# PCIE_CAP_REGS register map
Vendor: Texas Instruments
Peripheral module from a debugger description file (folder 66AK2G0x_66AK2G1x).
Registers are 32-bit, read-only, reset 0x0 unless marked. A register's access mark holds for its fields unless they carry their own. Offsets are as the file gives them; lines under a group give offsets from that group; [hi:lo] are bit positions; {n}, {i} and the like mark numbered series; 'fields as' and 'values as' point back to an identical list; <NAME> marks a mode.

## PCIE_CAP_REGS
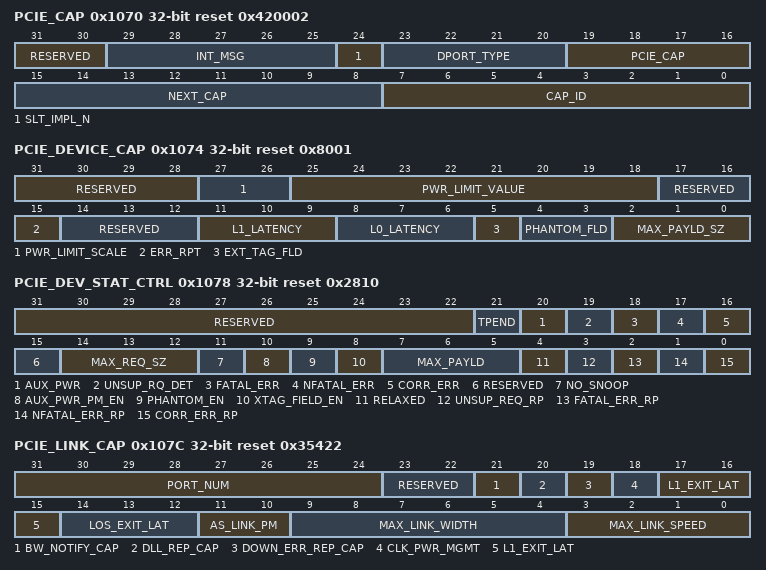
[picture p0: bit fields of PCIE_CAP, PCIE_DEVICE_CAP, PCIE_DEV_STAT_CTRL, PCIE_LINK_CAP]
0x1070 PCIE_CAP reset 0x420002
  [31:30] RESERVED — Reads return 0 and writes have no effect.
  [29:25] INT_MSG — Interrupt Message Number. Updated by hardware and writable through internal bus Interface.
  [24] SLT_IMPL_N — Slot Implemented. Writable from internal bus interface.
  [23:20] DPORT_TYPE — Device Port Type.
  [19:16] PCIE_CAP — PCI Express Capability Version
  [15:8] NEXT_CAP — Next capability pointer. Writable from internal bus interface.
  [7:0] CAP_ID — PCIe Capability ID.
0x1074 PCIE_DEVICE_CAP reset 0x8001
  [31:28] RESERVED — Reads return 0 and writes have no effect.
  [27:26] PWR_LIMIT_SCALE — Captured Slot Power Limit Scale. For upstream ports (EP ports) only.
  [25:18] PWR_LIMIT_VALUE — Captured Slot Power Limit Value. For upstream ports (EP ports) only.
  [17:16] RESERVED — Reads return 0 and writes have no effect.
  [15] ERR_RPT — Role-based Error Reporting. Writable from internal bus interface.
  [14:12] RESERVED — Reads return 0 and writes have no effect.
  [11:9] L1_LATENCY — Endpoint L1 Acceptable Latency. Must be
  [8:6] L0_LATENCY — Endpoint L0s Acceptable Latency. Must be
  [5] EXT_TAG_FLD — Extended Tag Field Supported. Writable from internal interface but should not be as the hardware is not capable.
  [4:3] PHANTOM_FLD — Phantom Field Supported. Writable from internal bus interface.
  [2:0] MAX_PAYLD_SZ — Maximum Payload size supported. Writable from internal bus interface.
0x1078 PCIE_DEV_STAT_CTRL access not given reset 0x2810
  [31:22] RESERVED ro — Reads return 0 and writes have no effect.
  [21] TPEND ro — Transaction Pending
  [20] AUX_PWR ro — Auxiliary Power Detected
  [19] UNSUP_RQ_DET — Unsupported Request Detected (access RW1C)
  [18] FATAL_ERR — Fatal Error Detected (access RW1C)
  [17] NFATAL_ERR — Non-fatal Error Detected (access RW1C)
  [16] CORR_ERR — Correctable Error Detected (access RW1C)
  [15] RESERVED ro — Reads return 0 and writes have no effect.
  [14:12] MAX_REQ_SZ rw — Maximum Read Request Size
  [11] NO_SNOOP rw — Enable no snoop
  [10] AUX_PWR_PM_EN rw — AUX Power PM Enable
  [9] PHANTOM_EN rw — Phantom Function Enable
  [8] XTAG_FIELD_EN rw — Extended Tag Field Enable
  [7:5] MAX_PAYLD rw — Maximum Payload Size
  [4] RELAXED rw — Enable Relaxed Ordering
  [3] UNSUP_REQ_RP rw — Enable Unsupported Request Reporting
  [2] FATAL_ERR_RP rw — Fatal Error Reporting Enable
  [1] NFATAL_ERR_RP rw — Non-fatal Error Reporting Enable
  [0] CORR_ERR_RP rw — Correctable Error Reporting Enable
0x107C PCIE_LINK_CAP reset 0x35422
  [31:24] PORT_NUM — Port Number. Writable from internal bus interface.
  [23:22] RESERVED — Reads return 0 and writes have no effect.
  [21] BW_NOTIFY_CAP — Link Bandwidth Notification Capable.
  [20] DLL_REP_CAP — Data Link Layer Active Reporting Capable.
  [19] DOWN_ERR_REP_CAP — Surprise Down Error Reporting Capable. Not supported. Always zero.
  [18] CLK_PWR_MGMT — Clock Power Management. Writable from internal bus interface.For upstream ports (EP Ports), a value of 1h in this bit indicates that the component tolerates the removal of any reference clock(s) in the L1 and L2/L3 Ready Link states. A value of 0 indicates the reference clock(s) must not be removed in these Link states. For downstream ports (RC Ports), this bit is always 0.
  [17:15] L1_EXIT_LAT — L1 Exit Latency when common clock is used. Writable from internal bus interface.
  [14:12] LOS_EXIT_LAT — L0s Exit Latency. Writable from internal bus interface.
  [11:10] AS_LINK_PM — Active State Link Power Management Support. Writable from internal bus interface.
  [9:4] MAX_LINK_WIDTH — Maximum Link Width (×N – corresponding to N Lanes). Writable from internal bus interface.
  [3:0] MAX_LINK_SPEED — Maximum Link Speed. Writable from internal bus interface.
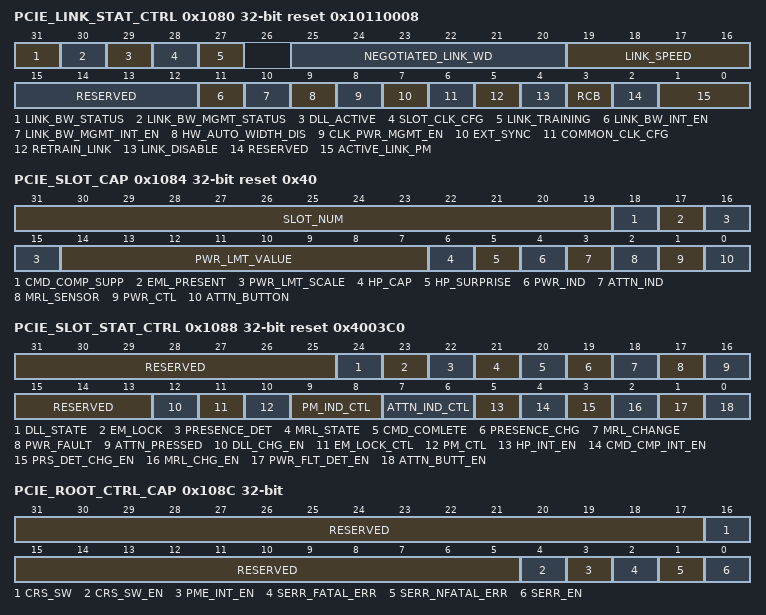
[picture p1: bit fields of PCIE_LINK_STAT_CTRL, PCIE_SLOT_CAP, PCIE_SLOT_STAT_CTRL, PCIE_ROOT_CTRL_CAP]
0x1080 PCIE_LINK_STAT_CTRL access not given reset 0x10110008
  [31] LINK_BW_STATUS — Link Autonomous Bandwidth Status.This bit is Set by hardware to indicate that hardware has autonomously changed Link speed or width, without the Port transitioning through DL_Down status, for reasons other than to attempt to correct unreliable Link operation. This bit must be set if the Physical Layer reports a speed or width change was initiated by the downstream component that was indicated as an autonomous change. Not applicable and reserved for EP. (access RW1C)
  [30] LINK_BW_MGMT_STATUS — Link Bandwidth Management Status.This bit is Set by hardware to indicate that either of the following has occurred without the Port transitioning through DL_Down status: • A Link retraining has completed following a write of 1b to the Retrain Link bit • Hardware has changed Link speed or width to attempt to correct unreliable Link operation, either through an LTSSM timeout or a higher level process. This bit must be set if the Physical Layer reports a speed or width change was initiated by the downstream component that was not indicated as an autonomous change. Not applicable and reserved for EP. (access RW1C)
  [29] DLL_ACTIVE ro — Data Link Layer ActiveThis bit indicates the status of the Data Link Control and Management State Machine. It returns a 1 to indicate the DL_Active state, 0 otherwise. Not applicable and reserved for EP.
  [28] SLOT_CLK_CFG ro — Slot Clock Configuration. Writable from internal bus interface.This bit indicates that the component uses the same physical reference clock that the platform provides on the connector.
  [27] LINK_TRAINING ro — Link Training. Not applicable to EP.
  [25:20] NEGOTIATED_LINK_WD ro — Negotiated Link Width. Set automatically by hardware after link initialization.
  [19:16] LINK_SPEED ro — Link Speed. Set automatically by hardware after link initialization.
  [15:12] RESERVED ro — Reads return 0 and writes have no effect.
  [11] LINK_BW_INT_EN ro — Link Autonomous Bandwidth Interrupt Enable. Not applicable and is reserved for EP.
  [10] LINK_BW_MGMT_INT_EN ro — Link Bandwidth Management Interrupt Enable. Not applicable and is reserved for EP.
  [9] HW_AUTO_WIDTH_DIS ro — Hardware Autonomous Width Disable. Not supported and hardwired to zero.
  [8] CLK_PWR_MGMT_EN rw — Enable Clock Power Management.
  [7] EXT_SYNC rw — Extended Synchronization.
  [6] COMMON_CLK_CFG rw — Common Clock Configuration.
  [5] RETRAIN_LINK rw — Retrain Link. Not applicable and reserved for EP.
  [4] LINK_DISABLE rw — This bit disables the link by directing the LTSSM to the Disabled state when set. Not applicable and is reserved for EP.
  [3] RCB ro — Read Completion Boundary. Writable via internal bus interface for RC.
  [2] RESERVED ro — Reads return 0 and writes have no effect.
  [1:0] ACTIVE_LINK_PM rw — Active State Link Power Management Control
0x1084 PCIE_SLOT_CAP reset 0x40
  [31:19] SLOT_NUM — Physical Slot Number. Writable from internal bus interface.
  [18] CMD_COMP_SUPP — No Command Complete Support. Writable from internal bus interface.When Set, this bit indicates that this slot does not generate software notification when an issued command is completed by the Hot-Plug Controller.
  [17] EML_PRESENT — Electromechanical Interlock Present. Writable from internal bus interface.When Set, this bit indicates that an Electromechanical Interlock is implemented on the chassis for this slot.
  [16:15] PWR_LMT_SCALE — Slot Power Limit Scale. Writable from internal bus interface.
  [14:7] PWR_LMT_VALUE — Slow Power Limit Value. Writable from internal bus interface.
  [6] HP_CAP — Hot Plug Capable. Writable from internal bus interface.
  [5] HP_SURPRISE — Hot Plug Surprise. Writable from internal bus interface.
  [4] PWR_IND — Power Indicator Present. Writable from internal bus interface.
  [3] ATTN_IND — Attention Indicator Present. Writable from internal bus interface.
  [2] MRL_SENSOR — MRL Sensor Present. Writable from internal bus interface.
  [1] PWR_CTL — Power Controller Present. Writable from internal bus interface. If there is no power controller, software must ensure that system power is up before reading Presence Detect state.
  [0] ATTN_BUTTON — Attention Indicator Present. Writable from internal bus interface.
0x1088 PCIE_SLOT_STAT_CTRL access not given reset 0x4003C0
  [31:25] RESERVED ro — Reads return 0 and writes have no effect.
  [24] DLL_STATE — Data Link Layer State Changed (access RW1C)
  [23] EM_LOCK ro — Electromechanical Lock Status
  [22] PRESENCE_DET ro — Presence Detect State
  [21] MRL_STATE ro — MRL Sensor State
  [20] CMD_COMLETE — Command Completed (access RW1C)
  [19] PRESENCE_CHG — Presence Detect Changed (access RW1C)
  [18] MRL_CHANGE — MRL Sensor Changed (access RW1C)
  [17] PWR_FAULT — Power Fault Detected (access RW1C)
  [16] ATTN_PRESSED — Attention Button Pressed. (access RW1C)
  [15:13] RESERVED ro — Reads return 0 and writes have no effect.
  [12] DLL_CHG_EN rw — Data Link Layer State Changed Enable.
  [11] EM_LOCK_CTL rw — Electromechanical Interlock Control.
  [10] PM_CTL rw — Power Controller Control
  [9:8] PM_IND_CTL rw — Power Indicator Control
  [7:6] ATTN_IND_CTL rw — Attention Indicator Control.
  [5] HP_INT_EN rw — Hot Plug Interrupt Enable.
  [4] CMD_CMP_INT_EN rw — Command Completed Interrupt Enable.
  [3] PRS_DET_CHG_EN rw — Presence Detect Changed Enable.
  [2] MRL_CHG_EN rw — MRL Sensor Changed Enable.
  [1] PWR_FLT_DET_EN rw — Power Fault Detected Enable.
  [0] ATTN_BUTT_EN rw — Attention Button Pressed Enable.
0x108C PCIE_ROOT_CTRL_CAP access per field
  [31:17] RESERVED ro — Reads return 0 and writes have no effect.
  [16] CRS_SW ro — CRS Software Visibility. Not supported and set to 0.
  [15:5] RESERVED ro — Reads return 0 and writes have no effect.
  [4] CRS_SW_EN ro — CRS Software Visibility Enable. Not supported and set to 0x0.
  [3] PME_INT_EN rw — PME Interrupt Enable
  [2] SERR_FATAL_ERR rw — System Error on Fatal Error Enable
  [1] SERR_NFATAL_ERR rw — System Error on Non-fatal Error Enable
  [0] SERR_EN rw — System Error on Correctable Error Enable
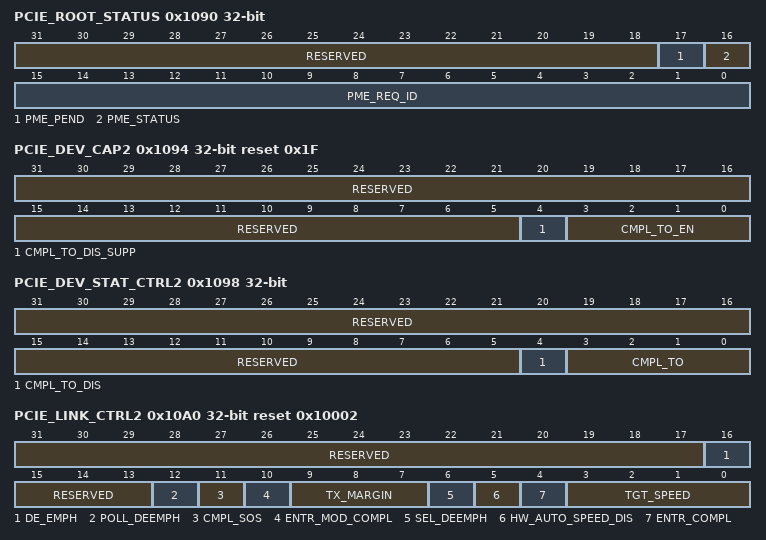
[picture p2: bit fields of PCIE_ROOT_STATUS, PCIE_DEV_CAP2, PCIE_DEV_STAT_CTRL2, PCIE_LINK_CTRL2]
0x1090 PCIE_ROOT_STATUS access not given
  [31:18] RESERVED ro — Reads return 0 and writes have no effect.
  [17] PME_PEND ro — Indicates that another PME is pending when the PME Status bit is Set.
  [16] PME_STATUS — Indicates that PME was asserted by the PME Requester. (access RW1C)
  [15:0] PME_REQ_ID ro — ID of the last PME Requester.This field is only valid when the PME Status bit is Set.
0x1094 PCIE_DEV_CAP2 reset 0x1F
  [31:5] RESERVED — Reads return 0 and writes have no effect.
  [4] CMPL_TO_DIS_SUPP — Completion timeout disable supported
  [3:0] CMPL_TO_EN — Completion timeout ranges supported. Applicable to RC/EP that issue requests on own behalf.
0x1098 PCIE_DEV_STAT_CTRL2 access per field
  [31:5] RESERVED ro — Reads return 0 and writes have no effect.
  [4] CMPL_TO_DIS rw — Completion timeout disable
  [3:0] CMPL_TO rw — Completion timeout value.It is strongly recommended that the Completion Timeout mechanism not expire in less than 10 ms.
0x10A0 PCIE_LINK_CTRL2 access per field reset 0x10002
  [31:17] RESERVED ro — Reads return 0 and writes have no effect.
  [16] DE_EMPH ro — Current De-emphasis level
  [15:13] RESERVED ro — Reads return 0 and writes have no effect.
  [12] POLL_DEEMPH rw — De-emphasis level in polling-compliance stateThis bit sets the de-emphasis level in Polling Compliance state if the entry occurred due to the Enter Compliance bit being 1.
  [11] CMPL_SOS rw — Compliance SOS.When this bit is set to 1, the LTSSM is required to send SKP Ordered Sets periodically in between the modified compliance patterns.
  [10] ENTR_MOD_COMPL rw — Enter modified compliance.When this bit is set to 1, the device transmits Modified Compliance Pattern if the LTSSM enters Polling Compliance substate.
  [9:7] TX_MARGIN rw — Value of non-de-emphasized voltage level at transmitter pins.
  [6] SEL_DEEMPH rw — Selectable De-emphasis.When the Link is operating at 5.0 GT/s speed, this bit selects the level of de-emphasis for an upstream component. When the Link is operating at 2.5 GT/s speed, the setting of this bit has no effect.
  [5] HW_AUTO_SPEED_DIS rw — Hardware Autonomous Speed Disable.
  [4] ENTR_COMPL rw — Enter Compliance.Software is permitted to force a Link to enter Compliance mode at the speed indicated in the Target Link Speed field by setting this bit to 1 in both components on a Link and then initiating a hot reset on the Link.
  [3:0] TGT_SPEED rw — Target Link Speed.
